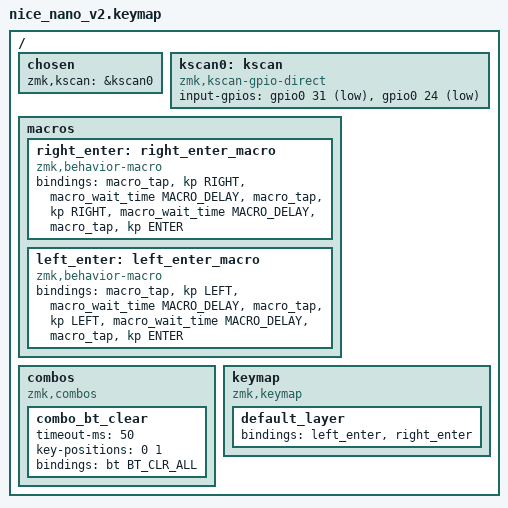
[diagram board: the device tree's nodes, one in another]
#include <behaviors.dtsi>
#include <dt-bindings/zmk/keys.h>
#include <dt-bindings/zmk/bt.h>

#define MACRO_DELAY 200

/ {
    chosen {
        zmk,kscan = &kscan0;
    };

    kscan0: kscan {
        compatible = "zmk,kscan-gpio-direct";
        
        input-gpios
            = <&gpio0 31 (GPIO_ACTIVE_LOW | GPIO_PULL_UP)>
            , <&gpio0 24 (GPIO_ACTIVE_LOW | GPIO_PULL_UP)>
            ;
    };

    macros {
        right_enter: right_enter_macro {
            compatible = "zmk,behavior-macro";
            #binding-cells = <0>;
            bindings
                = <&macro_tap &kp RIGHT>
                , <&macro_wait_time MACRO_DELAY>
                , <&macro_tap &kp RIGHT>
                , <&macro_wait_time MACRO_DELAY>
                , <&macro_tap &kp ENTER>
                ;
        };

        left_enter: left_enter_macro {
            compatible = "zmk,behavior-macro";
            #binding-cells = <0>;
            bindings
                = <&macro_tap &kp LEFT>
                , <&macro_wait_time MACRO_DELAY>
                , <&macro_tap &kp LEFT>
                , <&macro_wait_time MACRO_DELAY>
                , <&macro_tap &kp ENTER>
                ;
        };
    };

    combos {
        compatible = "zmk,combos";
        
        combo_bt_clear {
            timeout-ms = <50>;
            key-positions = <0 1>;
            bindings = <&bt BT_CLR_ALL>;
        };
    };

    keymap {
        compatible = "zmk,keymap";

        default_layer {
            bindings = <&left_enter &right_enter>;
        };
    };
};
